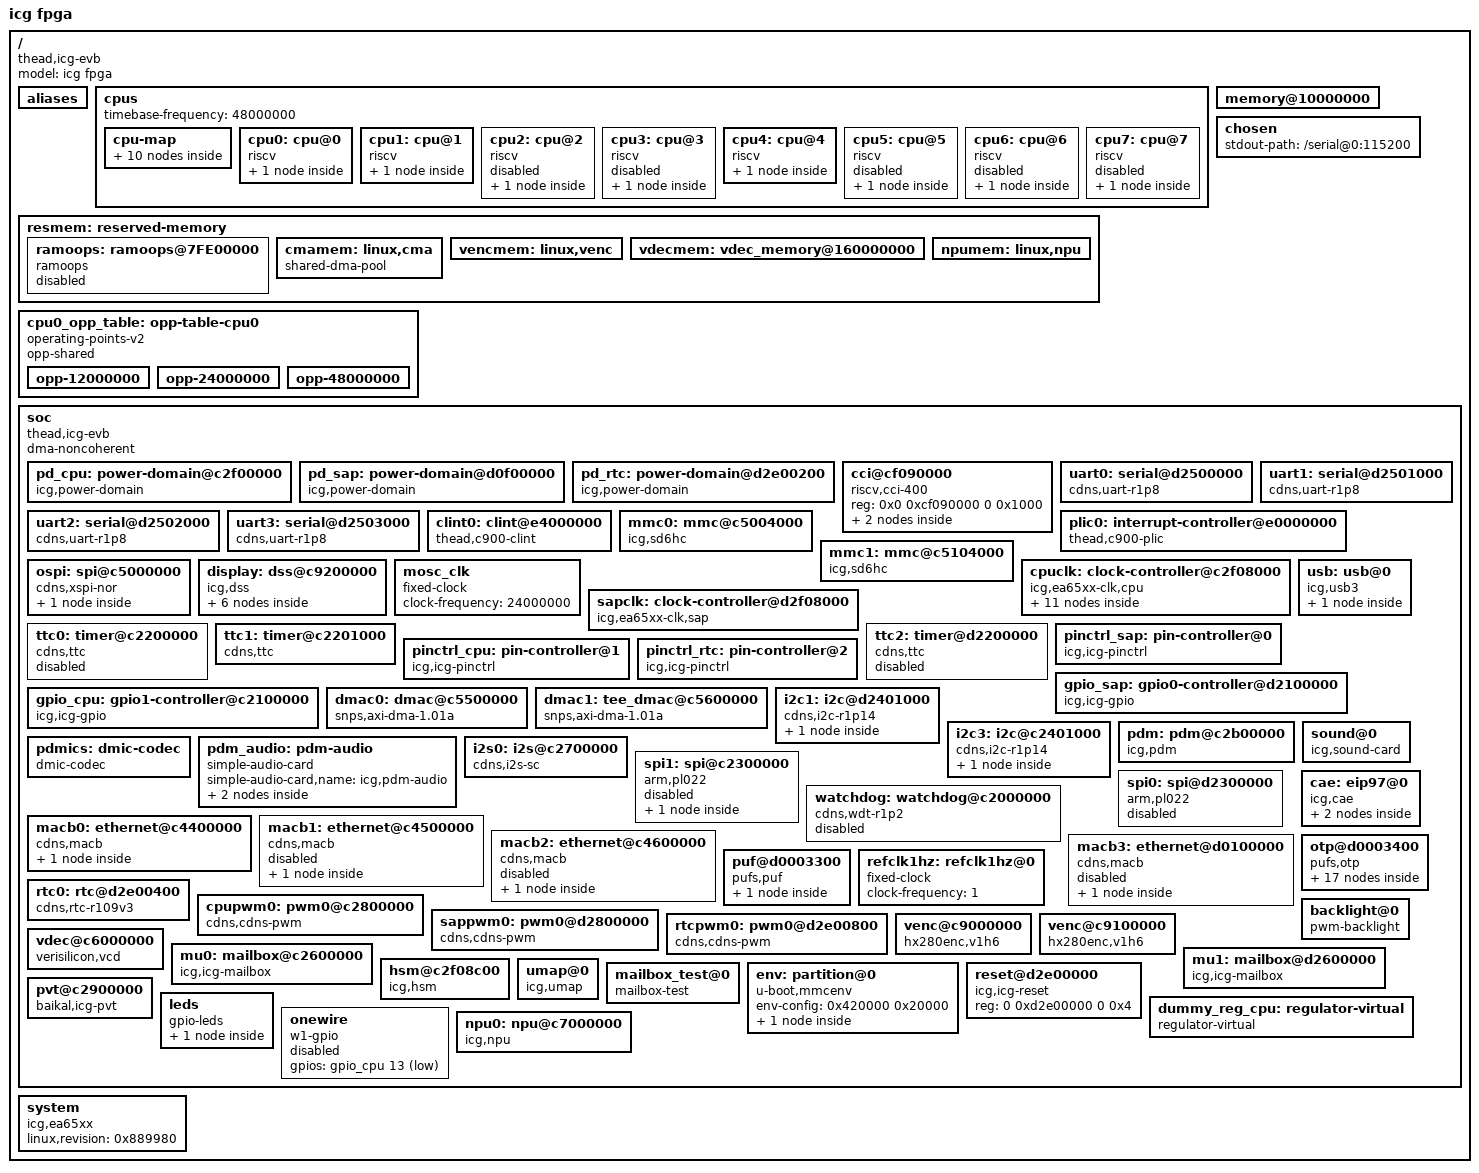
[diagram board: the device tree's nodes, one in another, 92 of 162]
/dts-v1/;
/ {
	model = "icg fpga";
	compatible = "thead,icg-evb";
	#address-cells = <2>;
	#size-cells = <2>;

	aliases {
		serial0 = &uart0;
		serial1 = &uart1;
		serial2 = &uart2;
		serial3 = &uart3;
		mmc0 = &mmc0;
		mmc1 = &mmc1;
		spi0 = &spi0;
		spi1 = &spi1;
		i2c1 = &i2c1;
		i2c3 = &i2c3;
		/*
			if no aliases provided, 
			driver will failed to get 
			index of a serial port, 
			lead to probe fail.
		*/
	};

	cpus {
		#address-cells = <1>;
		#size-cells = <0>;
		timebase-frequency = <48000000>;

		cpu-map {
			cluster0 {
				core0 {
					cpu = <&cpu0>;
				};
				core1 {
					cpu = <&cpu1>;
				};
				core2 {
					cpu = <&cpu2>;
				};
				core3 {
					cpu = <&cpu3>;
				};
			};
			cluster1 {
				core0 {
					cpu = <&cpu4>;
				};

				core1 {
					cpu = <&cpu5>;
				};

				core2 {
					cpu = <&cpu6>;
				};

				core3 {
					cpu = <&cpu7>;
				};
			};
		};

		cpu0:cpu@0 {
			device_type = "cpu";
			reg = <0>;
			status = "okay";
			compatible = "riscv";
			mmu-type = "riscv,sv39";
			riscv,isa = "rv64imafdc_zicbom_svpbmt_sstc_sscofpmf";
			riscv,cbom-block-size = <64>;
			cci-control-port = <&cci_control0>;
			cpu0_intc: interrupt-controller {
				#interrupt-cells = <1>;
				compatible = "riscv,cpu-intc";
				interrupt-controller;
			};
		};

		cpu1:cpu@1 {
			device_type = "cpu";
			reg = <1>;
			status = "okay";
			compatible = "riscv";
			mmu-type = "riscv,sv39";
			riscv,isa = "rv64imafdc_zicbom_svpbmt_sstc_sscofpmf";
			riscv,cbom-block-size = <64>;
			cci-control-port = <&cci_control0>;
			cpu1_intc: interrupt-controller {
				#interrupt-cells = <1>;
				compatible = "riscv,cpu-intc";
				interrupt-controller;
			};
		};

		cpu2:cpu@2 {
			device_type = "cpu";
			reg = <2>;
			status = "disabled";
			compatible = "riscv";
			mmu-type = "riscv,sv39";
			riscv,isa = "rv64imafdc_zicbom_svpbmt_sstc_sscofpmf";
			riscv,cbom-block-size = <64>;
			cci-control-port = <&cci_control0>;
			cpu2_intc: interrupt-controller {
				#interrupt-cells = <1>;
				compatible = "riscv,cpu-intc";
				interrupt-controller;
			};
		};

		cpu3:cpu@3 {
			device_type = "cpu";
			reg = <3>;
			status = "disabled";
			compatible = "riscv";
			mmu-type = "riscv,sv39";
			riscv,isa = "rv64imafdc_zicbom_svpbmt_sstc_sscofpmf";
			riscv,cbom-block-size = <64>;
			cci-control-port = <&cci_control0>;
			cpu3_intc: interrupt-controller {
				#interrupt-cells = <1>;
				compatible = "riscv,cpu-intc";
				interrupt-controller;
			};
		};

		cpu4:cpu@4 {
			device_type = "cpu";
			reg = <4>;
			status = "okay";
			compatible = "riscv";
			mmu-type = "riscv,sv39";
			riscv,isa = "rv64imafdc_zicbom_svpbmt_sstc_sscofpmf";
			riscv,cbom-block-size = <64>;
			cci-control-port = <&cci_control1>;
			cpu4_intc: interrupt-controller {
				#interrupt-cells = <1>;
				compatible = "riscv,cpu-intc";
				interrupt-controller;
			};
		};

		cpu5:cpu@5 {
			device_type = "cpu";
			reg = <5>;
			status = "disabled";
			compatible = "riscv";
			mmu-type = "riscv,sv39";
			riscv,isa = "rv64imafdc_zicbom_svpbmt_sstc_sscofpmf";
			riscv,cbom-block-size = <64>;
			cci-control-port = <&cci_control0>;
			cpu5_intc: interrupt-controller {
				#interrupt-cells = <1>;
				compatible = "riscv,cpu-intc";
				interrupt-controller;
			};
		};

		cpu6:cpu@6 {
			device_type = "cpu";
			reg = <6>;
			status = "disabled";
			compatible = "riscv";
			mmu-type = "riscv,sv39";
			riscv,isa = "rv64imafdc_zicbom_svpbmt_sstc_sscofpmf";
			riscv,cbom-block-size = <64>;
			cci-control-port = <&cci_control1>;
			cpu6_intc: interrupt-controller {
				#interrupt-cells = <1>;
				compatible = "riscv,cpu-intc";
				interrupt-controller;
			};
		};

		cpu7:cpu@7 {
			device_type = "cpu";
			reg = <7>;
			status = "disabled";
			compatible = "riscv";
			mmu-type = "riscv,sv39";
			riscv,isa = "rv64imafdc_zicbom_svpbmt_sstc_sscofpmf";
			riscv,cbom-block-size = <64>;
			cci-control-port = <&cci_control1>;
			cpu7_intc: interrupt-controller {
				#interrupt-cells = <1>;
				compatible = "riscv,cpu-intc";
				interrupt-controller;
			};
		};
	};

	memory@10000000{
		device_type = "memory";
		reg = <0x0 0x40200000 0x0 0x3fe00000
			0x1 0x40000000 0x0 0x40000000>;
	};

	chosen {
		stdout-path = "/serial@0:115200";
	};

	resmem: reserved-memory {
		#address-cells = <2>;
		#size-cells = <2>;
		ranges;

		ramoops: ramoops@7FE00000 {
			compatible = "ramoops";
			reg = <0x0 0x7FE00000 0x0 0x200000>;
			record-size = <0x8000>;
			console-size = <0x8000>;
			status = "disabled";
		};

		cmamem: linux,cma {
			compatible = "shared-dma-pool";
			reusable;
			size = <0 0x8000000>;
			alloc-ranges = <0 0x70000000 0 0xFE00000>;
			linux,cma-default;
		};

		vencmem: linux,venc {
			reg = <0x1 0x50000000 0x0 0x10000000>;
			no-map;
		};

		vdecmem: vdec_memory@160000000 {
			reg = <0x1 0x60000000 0x0 0x10000000>;
			no-map;
		};

		npumem: linux,npu {
		    reg = <0x1 0x80000000 0x0 0x10000000>;
			no-map;
		};
	};

	cpu0_opp_table: opp-table-cpu0 {
		compatible = "operating-points-v2";
		opp-shared;

		opp-12000000 {
			opp-hz = /bits/ 64 <12000000>;
			opp-microvolt = <600000>;
		};

		opp-24000000 {
			opp-hz = /bits/ 64 <24000000>;
			opp-microvolt = <700000>;
		};

		opp-48000000 {
			opp-hz = /bits/ 64 <48000000>;
			opp-microvolt = <800000>;
		};
	};

	soc {
		#address-cells = <2>;
		#size-cells = <2>;
		compatible = "thead,icg-evb", "simple-bus";
		dma-noncoherent;
		ranges;

		pd_cpu: power-domain@c2f00000 {
			compatible = "icg,power-domain";
			#power-domain-cells = <4>;
			domain-idx = <ICG_DOMAIN_CPU>;
			domain-nums = < 72 >;
		};

		pd_sap: power-domain@d0f00000 {
			compatible = "icg,power-domain";
			#power-domain-cells = <4>;
			domain-idx = <ICG_DOMAIN_SAP>;
			domain-nums = < 11 >;
		};

		pd_rtc: power-domain@d2e00200 {
			compatible = "icg,power-domain";
			#power-domain-cells = <4>;
			domain-idx = <ICG_DOMAIN_RTC>;
			domain-nums = < 2 >;
		};

		cci@cf090000 {
			compatible = "riscv,cci-400";
			#address-cells = <1>;
			#size-cells = <1>;
			reg = <0x0 0xcf090000 0 0x1000>;
			ranges = <0x0 0x0 0xcf090000 0x10000>;

			cci_control0: slave-if@5000 {
				compatible = "riscv,cci-400-ctrl-if";
				interface-type = "ace";
				reg = <0x5000 0x1000>;
			};

			cci_control1: slave-if@4000 {
				compatible = "riscv,cci-400-ctrl-if";
				interface-type = "ace";
				reg = <0x4000 0x1000>;
			};
		};

		uart0:serial@d2500000 {
				compatible = "cdns,uart-r1p8";
				reg = <0x0 0xd2500000 0x0 0x1000>;
				interrupt-parent = <&plic0>;
				interrupts = <S_UART0_IRQn IRQ_TYPE_LEVEL_HIGH>;
				clocks = <&sapclk  EA65XX_S_APB_CLK>, <&sapclk  EA65XX_S_UART_CLK>;
                clock-names = "pclk", "uart_clk";
				//power-domains = <&pd_sap EA65XX_PD_UART0_SAP ALWAYS_ON>;
		};

		uart1:serial@d2501000 {
        		compatible = "cdns,uart-r1p8";
        		reg = <0x0 0xd2501000 0x0 0x0400>;
        		interrupt-parent = <&plic0>;
        		interrupts = <S_UART1_IRQn IRQ_TYPE_LEVEL_HIGH>;
        		pinctrl-names = "default";
        		pinctrl-0 = <&pin_uart1>;
        		power-domains = <&pd_sap EA65XX_PD_UART1_SAP NORMAL>;
        		clocks = <&sapclk EA65XX_S_APB_CLK>, <&sapclk EA65XX_S_UART_CLK>;
        		clock-names = "pclk", "uart_clk";
		};

		uart2:serial@d2502000 {
        		compatible = "cdns,uart-r1p8";
        		reg = <0x0 0xd2502000 0x0 0x0400>;
        		interrupt-parent = <&plic0>;
        		interrupts = <C_UART2_IRQn IRQ_TYPE_LEVEL_HIGH>;
        		pinctrl-names = "default";
        		pinctrl-0 = <&pin_uart2>;
        		power-domains = <&pd_cpu EA65XX_PD_UART2_CPU NORMAL>;
        		clocks = <&cpuclk EA65XX_PAPB_CLK>, <&cpuclk EA65XX_UART_CLK>;
        		clock-names = "pclk", "uart_clk";
		};

		uart3:serial@d2503000 {
        		compatible = "cdns,uart-r1p8";
        		reg = <0x0 0xd2503000 0x0 0x0400>;
        		interrupt-parent = <&plic0>;
        		interrupts = <C_UART3_IRQn IRQ_TYPE_LEVEL_HIGH>;
        		pinctrl-names = "default";
        		pinctrl-0 = <&pin_uart3>;
        		power-domains = <&pd_cpu EA65XX_PD_UART3_CPU NORMAL>;
        		clocks = <&cpuclk EA65XX_PAPB_CLK>, <&cpuclk EA65XX_UART_CLK>;
        		clock-names = "pclk", "uart_clk";
		};

		clint0: clint@e4000000 {
			compatible = "thead,c900-clint";
			interrupts-extended = <
				&cpu0_intc 3 &cpu0_intc 7
				&cpu1_intc 3 &cpu1_intc 7
				&cpu2_intc 3 &cpu2_intc 7
				&cpu3_intc 3 &cpu3_intc 7
				&cpu4_intc 3 &cpu4_intc 7
				&cpu5_intc 3 &cpu5_intc 7
				&cpu6_intc 3 &cpu6_intc 7
				&cpu7_intc 3 &cpu7_intc 7
				>;
			reg = <0x0 0xe4000000 0x0 0x10000>;
			clint,has-no-64bit-mmio;
		};
	
		plic0: interrupt-controller@e0000000 {
			compatible = "thead,c900-plic";
			interrupt-controller;
			interrupts-extended = <
				&cpu0_intc  0xffffffff &cpu0_intc 9
				&cpu1_intc  0xffffffff &cpu1_intc 9
				&cpu2_intc  0xffffffff &cpu2_intc 9
				&cpu3_intc  0xffffffff &cpu3_intc 9
				&cpu4_intc  0xffffffff &cpu4_intc 9
				&cpu5_intc  0xffffffff &cpu6_intc 9
				&cpu6_intc  0xffffffff &cpu6_intc 9
				&cpu7_intc  0xffffffff &cpu7_intc 9
				>;
			reg = <0x0 0xe0000000 0x0 0x04000000>;
			#address-cells = <0>;
			#interrupt-cells = <2>;
			riscv,ndev = <194>;
		};

		mmc0: mmc@c5004000 {
			compatible = "icg,sd6hc";
			clock-names = "main";
			clocks = <&cpuclk EA65XX_EMMC0_CLK>;
			clock-frequency = <36000000>;
			reg = <0x0 0xc5004000 0x0 0x400>;
			power-domains = <&pd_cpu EA65XX_PD_EMMC0_CPU ALWAYS_ON>;
			interrupts-extended = <&plic0 C_EMMC0_IRQn IRQ_TYPE_LEVEL_HIGH>;
			bus-width = <1>;
			sdhci-caps-mask = <0x0 0x200000>;
			status = "disabled";
		};

		mmc1: mmc@c5104000 {
			compatible = "icg,sd6hc";
			clock-names = "main";
			clocks = <&cpuclk EA65XX_SD1_CLK>;
			clock-frequency = <36000000>;
			reg = <0x0 0xc5104000 0x0 0x400>;
			power-domains = <&pd_cpu EA65XX_PD_SD1_CPU ALWAYS_ON>;
			interrupts-extended = <&plic0 C_SD1_IRQn IRQ_TYPE_LEVEL_HIGH>;
			bus-width = <1>;
			sdhci-caps-mask = <0x0 0x200000>;
			no-1-8-v;
			status = "disabled";
		};

		ospi: spi@c5000000 {
			compatible = "cdns,xspi-nor";
			reg = <0x0 0xc5000000 0x0 0x1000>,
				<0x0 0x30000000 0x0 0x1000>,
				<0x0 0xC5f00000 0x0 0x1000>;
			reg-names = "io", "sdma", "pwr";
			interrupts-extended = <&plic0 C_XSPI0_IRQn IRQ_TYPE_LEVEL_HIGH>;
			pinctrl-names = "default";
			pinctrl-0 = <&pin_ospi>;
			status = "okay";
			#address-cells = <1>;
			#size-cells = <0>;

			flash@0 {
				compatible = "w25q128", "jedec,spi-nor";
				reg = <0>;/* Chip select must be 0/1 */
				#address-cells = <1>;
				#size-cells = <1>;
				spi-max-frequency = <4000000>;
			};
		};
		
		display: dss@c9200000 {
			compatible = "icg,dss";
			clocks = <&cpuclk  EA65XX_IDS_ETC_CLK>, <&cpuclk  EA65XX_IDS_EITF_CLK>;
			clock-names = "ids_etc", "ids_eitf";
			power-domains = <&pd_cpu EA65XX_PD_IDS_CPU ALWAYS_ON>;
			pinctrl-names = "default";
			pinctrl-0 = <&pin_ids>;
			status = "okay";
			port = "lcdc"; //lcdc or tvif
			det-gpios = <&gpio_cpu 89 GPIO_ACTIVE_HIGH>;
			overlay-nums = <1>;
			#address-cells = <2>;
			#size-cells = <2>;
			ranges;

			dispc@c9200000 {
				compatible = "icg,dispc";
				reg = <0x00 0xc9200000 0x00 0x8000>;
				interrupts-extended = <&plic0 C_IDS_IRQn IRQ_TYPE_LEVEL_HIGH>;
				interrupts = <25>;
			};

			lcdc@c9200000 {
				compatible = "icg,lcdc";
				bpp = <32>;
				reset-gpios = <&gpio_cpu 78 GPIO_ACTIVE_HIGH>;
				backlight-gpios = <&gpio_cpu 79 GPIO_ACTIVE_HIGH>;
				display-timings {
					native-mode = <&timing0>;
					timing0: 1024x600 {
						clock-frequency = <50000000>;
						hactive = <1024>;
						vactive = <600>;
						hfront-porch = <160>;
						hback-porch = <140>;
						hsync-len = <20>;
						vfront-porch = <12>;
						vback-porch = <20>;
						vsync-len = <3>;
						hsync-active = <0>;
						vsync-active = <0>;
						de-active = <0>;
						pixelclk-active = <0>;
					};
				};
			};

			tvif@c9200000 {
				compatible = "icg,tvif";
				mode = "bt1120"; //bt601 bt656
				standard = "pal";//"ntsc"
				width = <1280>;
				height = <720>;
			};

			fb@c9200000 {
				compatible = "icg,fb";
				status = "okay";
			};
		};

        mosc_clk: mosc_clk {
            #clock-cells = <0>;
            compatible = "fixed-clock";
            clock-frequency = <24000000>;
        };

		cpuclk: clock-controller@c2f08000 {
			#address-cells = <2>;
			#size-cells = <2>;
			clk-domain = <ICG_DOMAIN_CPU>;
			compatible = "icg,ea65xx-clk,cpu";
			reg = <0x0 0xc2f08000 0x0 0x1000>;
			#clock-cells = <1>;
			c_apll_clk {
				assigned-clocks = <&cpuclk EA65XX_APLL_CLK>;
				assigned-clock-rates = <48000000>;
			};

			c_dpll_clk {
				assigned-clocks = <&cpuclk EA65XX_DPLL_CLK>;
				assigned-clock-rates = <96000000>;
			};

			c_epll_clk {
				assigned-clocks = <&cpuclk EA65XX_EPLL_CLK>;
				assigned-clock-rates = <96000000>;
			};

			c_vpll_clk {
				assigned-clocks = <&cpuclk EA65XX_VPLL_CLK>;
				assigned-clock-rates = <96000000>;
			};

			c_bpll_clk {
				assigned-clocks = <&cpuclk EA65XX_BPLL_CLK>;
				assigned-clock-rates = <96000000>;
			};

			c_bus1_clk {
				assigned-clocks = <&cpuclk EA65XX_BUS1_CLK>;
				assigned-clock-rates = <96000000>;
			};

			c_bus2_clk {
				assigned-clocks = <&cpuclk EA65XX_BUS2_CLK>;
				assigned-clock-rates = <48000000>;
			};

			c_bus3_clk {
				assigned-clocks = <&cpuclk EA65XX_BUS3_CLK>;
				assigned-clock-rates = <48000000>;
			};

			c_bus4_clk {
				assigned-clocks = <&cpuclk EA65XX_BUS4_CLK>;
				assigned-clock-rates = <96000000>;
			};

			c_bus5_clk {
				assigned-clocks = <&cpuclk EA65XX_BUS5_CLK>;
				assigned-clock-rates = <24000000>;
			};

			c_bus6_clk {
				assigned-clocks = <&cpuclk EA65XX_BUS6_CLK>;
				assigned-clock-rates = <12000000>;
			};
		};

		sapclk: clock-controller@d2f08000 {
			#address-cells = <2>;
			#size-cells = <2>;
			clk-domain = <ICG_DOMAIN_SAP>;
			compatible = "icg,ea65xx-clk,sap";
			reg = <0x0 0xd2f08000 0x0 0x1000>;
			#clock-cells = <1>;
		};

		ttc0: timer@c2200000 {
			interrupts-extended =
				<&plic0 C_TTC0_TIMER0_IRQn IRQ_TYPE_LEVEL_HIGH>,
				<&plic0 C_TTC0_TIMER1_IRQn IRQ_TYPE_LEVEL_HIGH>,
				<&plic0 C_TTC0_TIMER2_IRQn IRQ_TYPE_LEVEL_HIGH>;
			power-domains = <&pd_cpu EA65XX_PD_TTC0_CPU ALWAYS_ON>;
			compatible = "cdns,ttc";
			clocks = <&cpuclk EA65XX_TTC_CLK>;
			timer-width = <32>;
			reg = <0x0 0xc2200000 0x0 0x1000>;
			status = "disable";
		};

		ttc1: timer@c2201000 {
			interrupts-extended =
				<&plic0 C_TTC1_TIMER0_IRQn IRQ_TYPE_LEVEL_HIGH>,
				<&plic0 C_TTC1_TIMER1_IRQn IRQ_TYPE_LEVEL_HIGH>,
				<&plic0 C_TTC1_TIMER2_IRQn IRQ_TYPE_LEVEL_HIGH>;
			power-domains = <&pd_cpu EA65XX_PD_TTC1_CPU ALWAYS_ON>;
			compatible = "cdns,ttc";
			clocks = <&cpuclk EA65XX_TTC_CLK>;
			timer-width = <32>;
			reg = <0x0 0xc2201000 0x0 0x1000>;
			status = "okay";
		};

		ttc2: timer@d2200000 {
			interrupts-extended =
				<&plic0 S_TTC0_TIMER0_IRQn IRQ_TYPE_LEVEL_HIGH>,
				<&plic0 S_TTC0_TIMER1_IRQn IRQ_TYPE_LEVEL_HIGH>,
				<&plic0 S_TTC0_TIMER2_IRQn IRQ_TYPE_LEVEL_HIGH>;
			power-domains = <&pd_sap EA65XX_PD_TTC_SAP ALWAYS_ON>;
			compatible = "cdns,ttc";
			clocks = <&sapclk  EA65XX_S_TTC_CLK>;
			timer-width = <32>;
			reg = <0x0 0xd2200000 0x0 0x1000>;
			status = "disable";
		};

		pinctrl_sap: pin-controller@0{
			reg = <0 0xd2f09000 0 0x400>;
			compatible = "icg,icg-pinctrl";
			pin-domain = <ICG_DOMAIN_SAP>;
			pin-base = <ICG_PIN_SAP_START>;
			npins = <ICG_PIN_PER_DOMAIN_CNT>;
		};

		pinctrl_cpu: pin-controller@1{
			reg = <0 0xc2f09000 0 0x400>;
			compatible = "icg,icg-pinctrl";
			pin-domain = <ICG_DOMAIN_CPU>;
			pin-base = <ICG_PIN_CPU_START>;
			npins = <ICG_PIN_PER_DOMAIN_CNT>;
		};

		pinctrl_rtc: pin-controller@2{
			reg = <0 0xd2e00040 0 0x40>;
			compatible = "icg,icg-pinctrl";
			pin-domain = <ICG_DOMAIN_RTC>;
			pin-base = <ICG_PIN_RTC_START>;
			npins = <ICG_PIN_PER_DOMAIN_CNT>;
		};

		usb: usb@0  {
			compatible = "icg,usb3";
			power-domains = <&pd_cpu EA65XX_PD_USB0_CPU NORMAL>;
			clocks = <&cpuclk EA65XX_USB_LPM_CLK>, 
					<&cpuclk EA65XX_USB_APP_CLK>,
					<&cpuclk EA65XX_USB_STB_CLK>,
					<&cpuclk EA65XX_USB2_REF_CLK>,
					<&cpuclk EA65XX_USB3_REF_CLK>;
			clock-names = "lpm", "app", "stb", "ref2", "ref3";
			//assigned-clocks = <&cpuclk IMX_SC_R_USB_2 IMX_SC_PM_CLK_MST_BUS>;
			//assigned-clock-rates = <250000000>;
			usb0_id_det-gpios = <&gpio_cpu 89 GPIO_ACTIVE_HIGH>;
			//usb1_id_det-gpios = <&gpio_cpu 90 GPIO_ACTIVE_HIGH>;
			//usb2_id_det-gpios = <&gpio_cpu 91 GPIO_ACTIVE_HIGH>;
			//usb3_id_det-gpios = <&gpio_cpu 92 GPIO_ACTIVE_HIGH>;

			#address-cells = <2>;
			#size-cells = <2>;
			ranges;

			usb0: usb@c4000000 {
				compatible = "cdns,usb3";
				reg = <0x00 0xc4000000 0x00 0x10000>,
					  <0x00 0xc4010000 0x00 0x10000>,
					  <0x00 0xc4020000 0x00 0x10000>;
				reg-names = "otg", "xhci", "dev";
				interrupt-parent = <&plic0>;
				interrupts = <C_USB0_HOST_IRQn	IRQ_TYPE_LEVEL_HIGH
							C_USB0_DEVICE_IRQn	IRQ_TYPE_LEVEL_HIGH
							C_USB0_OTG_IRQn		IRQ_TYPE_LEVEL_HIGH>;
				interrupt-names = "host", "peripheral", "otg";
				maximum-speed = "super-speed";
				dr_mode = "peripheral";
			};
		};

		gpio_sap: gpio0-controller@d2100000 {
			compatible = "icg,icg-gpio";
			reg = <0x0 0xd2100000 0x0 0x1000>;
			power-domains = <&pd_sap EA65XX_PD_GPIO_SAP ALWAYS_ON>;
			#gpio-cells = <2>;
			gpio-base = <ICG_PIN_SAP_START>;
			ngpios = <18>;
			gpio-controller;
			interrupt-controller;
			interrupt-parent = <&plic0>;
			interrupts = <S_GPIO0_IRQn IRQ_TYPE_LEVEL_HIGH>;
		};

		gpio_cpu: gpio1-controller@c2100000 {
			compatible = "icg,icg-gpio";
			reg = <0x0 0xc2100000 0x0 0x1000>;
			power-domains = <&pd_cpu EA65XX_PD_GPIO_CPU ALWAYS_ON>;
			#gpio-cells = <2>;
			gpio-base = <ICG_PIN_CPU_START>;
			ngpios = <99>;
			gpio-controller;
			interrupt-controller;
			interrupt-parent = <&plic0>;
			interrupts = 	<C_GPIO0_IRQn IRQ_TYPE_LEVEL_HIGH>,
							<C_GPIO1_IRQn IRQ_TYPE_LEVEL_HIGH>,
							<C_GPIO2_IRQn IRQ_TYPE_LEVEL_HIGH>,
							<C_GPIO3_IRQn IRQ_TYPE_LEVEL_HIGH>;
		};

		dmac0: dmac@c5500000 {
			compatible = "snps,axi-dma-1.01a";
			reg = <0x0 0xc5500000 0x0 0x1000>;
			interrupt-parent = <&plic0>;
			interrupts = <C_DMA0_IRQn IRQ_TYPE_LEVEL_HIGH>;
			dma-noncoherent;
			clocks = <&cpuclk EA65XX_BUS2_CLK>, <&cpuclk EA65XX_PAPB_CLK>;
			clock-names = "core-clk", "cfgr-clk";
			power-domains = <&pd_cpu EA65XX_PD_DMA0_CPU ALWAYS_ON>;
			#dma-cells = <1>;
			dma-channels = <8>;
			snps,block-size = <65536 65536 65536 65536 65536 65536 65536 65536>;
			snps,priority = <0 1 2 3 4 5 6 7>;
			snps,dma-masters = <1>;
			snps,data-width = <4>;
			snps,axi-max-burst-len = <16>;
			status = "okay";
		};

		dmac1: tee_dmac@c5600000 {
			compatible = "snps,axi-dma-1.01a";
			reg = <0x0 0xc5600000 0x0 0x1000>;
			interrupt-parent = <&plic0>;
			interrupts = <C_DMA1_IRQn IRQ_TYPE_LEVEL_HIGH>;
			dma-noncoherent;
			clocks = <&cpuclk EA65XX_BUS2_CLK>, <&cpuclk EA65XX_PAPB_CLK>;
			clock-names = "core-clk", "cfgr-clk";
			power-domains = <&pd_cpu EA65XX_PD_DMA1_CPU ALWAYS_ON>;
			#dma-cells = <1>;
			dma-channels = <8>;
			snps,block-size = <65536 65536 65536 65536 65536 65536 65536 65536>;
			snps,priority = <0 1 2 3 4 5 6 7>;
			snps,dma-masters = <1>;
			snps,data-width = <4>;
			snps,axi-max-burst-len = <16>;
			status = "okay";
		};

		i2c1: i2c@d2401000 {
			compatible = "cdns,i2c-r1p14";
			reg = <0x0 0xd2401000 0x0 0x1000>;
			#address-cells = <1>;
			#size-cells = <0>;
			interrupt-parent = <&plic0>;
			interrupts = <S_IIC1_IRQn IRQ_TYPE_LEVEL_HIGH>;
			clock-frequency = <100000>;
			clocks = <&sapclk  EA65XX_S_APB_CLK>;
			power-domains = <&pd_sap EA65XX_PD_IIC1_SAP ALWAYS_ON>;
			pinctrl-names = "default";
			pinctrl-0 = <&pin_i2c1>;

			eeprom@50{
				compatible = "slave-24c02";
				reg = <0x50>;
				pagesize = <1>;
			};
		};
		
		i2c3: i2c@c2401000 {
			compatible = "cdns,i2c-r1p14";
			reg = <0x0 0xc2401000 0x0 0x1000>;
			#address-cells = <1>;
			#size-cells = <0>;
			interrupt-parent = <&plic0>;
			interrupts = <C_IIC3_IRQn IRQ_TYPE_LEVEL_HIGH>;
			clock-frequency = <100000>;
			clocks = <&cpuclk EA65XX_PAPB_CLK>;
			power-domains = <&pd_cpu EA65XX_PD_IIC3_CPU ALWAYS_ON>;
			pinctrl-names = "default";
			pinctrl-0 = <&pin_i2c3>;

			es8388: codec@11{
				compatible = "everest,es8388";
				reg = <0x11>;
				pagesize = <1>;
			};
		};

		pdm: pdm@c2b00000 {
			compatible = "icg,pdm";
			reg = <0x0 0xc2b00000 0x0 0x4000>;
			//interrupt-parent = <&plic0>;
			//interrupts = <C_DMAC0_IRQn IRQ_TYPE_LEVEL_HIGH>;
			dmas = <&dmac1 6>, <&dmac1 7>, <&dmac1 8>, <&dmac1 9>;
			dma-names = "rx0", "rx1", "rx2", "rx3";
			multi-dma-rx = <1>;
			mul-dma-rx-num = <4>;
			clocks = <&cpuclk EA65XX_DMIC_CLK>;
			clock-names = "pdm-clk";
			pinctrl-names = "default";
			pinctrl-0 = <&pin_dmic>;
			power-domains = <&pd_cpu EA65XX_PD_DMIC_CPU ALWAYS_ON>;
			#sound-dai-cells = <0>;
			status = "okay";
		};

		pdmics: dmic-codec {
			status = "okay";
			compatible = "dmic-codec";
			#sound-dai-cells = <0>;
		};

		pdm_audio: pdm-audio {
			status = "okay";
			compatible = "simple-audio-card";
			simple-audio-card,name = "icg,pdm-audio";
			simple-audio-card,cpu {
				sound-dai = <&pdm>;
			};
			simple-audio-card,codec {
				sound-dai = <&pdmics>;
			};
		};

		i2s0: i2s@c2700000 {
			compatible = "cdns,i2s-sc";
			reg = <0x0 0xc2700000 0x0 0x1000>;
			#address-cells = <1>;
			#size-cells = <0>;
			//interrupt-parent = <&plic0>;
			//interrupts = <C_IIS0_IRQn IRQ_TYPE_LEVEL_HIGH>;
			clocks = <&cpuclk EA65XX_IIS_CLK>;
			power-domains = <&pd_cpu EA65XX_PD_IIS0_CPU ALWAYS_ON>;
			pinctrl-names = "default";
			pinctrl-0 = <&pin_i2s0>;
			dmas = <&dmac0 10>, <&dmac0 11>;
			dma-names = "tx","rx";
		};

		sound@0 {
			compatible = "icg,sound-card";
			i2s-controller = <&i2s0>;
			sound-codec = <&es8388>;
		};

		spi1: spi@c2300000 {
			compatible = "arm,pl022", "arm,primecell";
			arm,primecell-periphid = <0x00041022>;
			reg = <0x0 0xc2300000 0x0 0x1000>;
			interrupts-extended = <&plic0 C_SPI1_IRQn IRQ_TYPE_LEVEL_HIGH>;
			#address-cells = <1>;
			#size-cells = <0>;
			num-cs = <1>;
			power-domains = <&pd_cpu EA65XX_PD_SPI1_CPU NORMAL>;
			pinctrl-names = "default";
			pinctrl-0 = <&pin_spi1>;
			cs-gpios = <&gpio_cpu 48 GPIO_ACTIVE_LOW>;
			status = "disabled";
			clocks = <&sapclk  EA65XX_S_SSP_CLK>;
			clock-names = "apb_pclk";
			flash0:flash@0 {
				compatible = "w25q128", "jedec,spi-nor";
				reg = <0>;   
				spi-max-frequency = <4000000>;
				
			};
		};

		spi0: spi@d2300000 {
			compatible = "arm,pl022", "arm,primecell";
			arm,primecell-periphid = <0x00041022>;
			reg = <0x0 0xd2300000 0x0 0x1000>;
			interrupts-extended = <&plic0 S_SPI0_IRQn IRQ_TYPE_LEVEL_HIGH>;
			#address-cells = <1>;
			#size-cells = <0>;
			num-cs = <1>;
			power-domains = <&pd_sap EA65XX_PD_SPI0_SAP NORMAL>;
			pinctrl-names = "default";
			pinctrl-0 = <&pin_spi0>;
			cs-gpios = <&gpio_sap 7 GPIO_ACTIVE_LOW>;
			status = "disabled";
			clocks = <&sapclk  EA65XX_S_SSP_CLK>;
			clock-names = "apb_pclk";
		};

		watchdog: watchdog@c2000000 {
			compatible = "cdns,wdt-r1p2";
			reg = <0x0 0xc2000000 0x0 0x1000>;
			interrupts-extended = <&plic0 C_WDT_IRQn IRQ_TYPE_LEVEL_HIGH>;
			power-domains = <&pd_cpu EA65XX_PD_WDT_CPU ALWAYS_ON>;
			clocks = <&cpuclk EA65XX_PAPB_CLK>;
			reset-on-timeout = <1>;
			status = "disabled";
		};

		macb0: ethernet@c4400000 {
			compatible = "cdns,macb";
			reg = <0x0 0xc4400000 0x0 0x2000
				0x0 0xc4f01000 0x0 0x2000>;
			power-domains = <&pd_cpu EA65XX_PD_GMAC0_CPU NORMAL>;
			clock-names = "pclk", "hclk", "tx_clk", "rx_clk", "tsu_clk";
			clocks = <&cpuclk EA65XX_PAPB_CLK>, <&cpuclk EA65XX_GMAC_GTX_CLK>, <&cpuclk EA65XX_GMAC_REF_CLK>, <&cpuclk EA65XX_GMAC_REF_CLK>, <&cpuclk EA65XX_GMAC_TSU_CLK>;
			interrupts = <C_GMAC0_Q_IRQn IRQ_TYPE_LEVEL_HIGH>,
								   <C_GMAC0_Q_IRQn IRQ_TYPE_LEVEL_HIGH>,
									 <C_GMAC0_Q_IRQn IRQ_TYPE_LEVEL_HIGH>;
			interrupt-parent = <&plic0>;
			pinctrl-names = "default";
			pinctrl-0 = <&pin_macb0>;
			phy-mode = "rmii";
			local-mac-address = [e6 e8 dc ff db de];
			reset-gpios = <&gpio_cpu 41 GPIO_ACTIVE_LOW>;
			reset-delay-us = <150000>;
			reset-post-delay-us = <100000>;
			status = "okay";
			#address-cells = <1>;
			#size-cells = <0>;

			ethernet-phy@0 {
				compatible = "ethernet-phy-ieee802.3-c22";
				reg = <0x0>;
			};
		};

		macb1: ethernet@c4500000 {
			compatible = "cdns,macb";
			reg = <0x0 0xc4500000 0x0 0x2000
				0x0 0xc4f01400 0x0 0x2000>;
			power-domains = <&pd_cpu EA65XX_PD_GMAC1_CPU NORMAL>;
			clock-names = "pclk", "hclk", "tx_clk", "rx_clk", "tsu_clk";
			clocks = <&cpuclk EA65XX_PAPB_CLK>, <&cpuclk EA65XX_GMAC_GTX_CLK>, <&cpuclk EA65XX_GMAC_REF_CLK>, <&cpuclk EA65XX_GMAC_REF_CLK>, <&cpuclk EA65XX_GMAC_TSU_CLK>;
			interrupts = <C_GMAC1_Q_IRQn IRQ_TYPE_LEVEL_HIGH>,
								 	 <C_GMAC1_Q_IRQn IRQ_TYPE_LEVEL_HIGH>,
									 <C_GMAC1_Q_IRQn IRQ_TYPE_LEVEL_HIGH>;
			interrupt-parent = <&plic0>;
			pinctrl-names = "default";
			pinctrl-0 = <&pin_macb1>;
			phy-mode = "rgmii";
			local-mac-address = [e6 e8 dc ff db de];
			reset-gpios = <&gpio_cpu 57 GPIO_ACTIVE_LOW>;
			reset-delay-us = <150000>;
			reset-post-delay-us = <100000>;
			txc-skew-ps = <0>;
			rxc-skew-ps = <0>;
			status = "disabled";
			#address-cells = <1>;
			#size-cells = <0>;

			ethernet-phy@0 {
				compatible = "ethernet-phy-ieee802.3-c22";
				reg = <0x0>;
			};
		};

		macb2: ethernet@c4600000 {
			compatible = "cdns,macb";
			reg = <0x0 0xc4600000 0x0 0x100000
				0x0 0xc4f01800 0x0 0x400>;
			power-domains = <&pd_cpu EA65XX_PD_GMAC2_CPU NORMAL>;
			clock-names = "pclk", "hclk", "tx_clk", "rx_clk", "tsu_clk";
			clocks = <&cpuclk EA65XX_PAPB_CLK>, <&cpuclk EA65XX_GMAC_GTX_CLK>, <&cpuclk EA65XX_GMAC_REF_CLK>, <&cpuclk EA65XX_GMAC_REF_CLK>, <&cpuclk EA65XX_GMAC_TSU_CLK>;
			interrupts = <C_GMAC2_Q_IRQn IRQ_TYPE_LEVEL_HIGH>,
									 <C_GMAC2_Q_IRQn IRQ_TYPE_LEVEL_HIGH>,
									 <C_GMAC2_Q_IRQn IRQ_TYPE_LEVEL_HIGH>;
			interrupt-parent = <&plic0>;
			pinctrl-names = "default";
			pinctrl-0 = <&pin_macb2>;
			phy-mode = "rgmii";
			local-mac-address = [e6 e8 dc ff db de];
			reset-gpios = <&gpio_cpu 57 GPIO_ACTIVE_LOW>;
			reset-delay-us = <150000>;
			reset-post-delay-us = <100000>;
			txc-skew-ps = <0>;
			rxc-skew-ps = <0>;
			status = "disabled";
			#address-cells = <1>;
			#size-cells = <0>;

			ethernet-phy@0 {
				compatible = "ethernet-phy-ieee802.3-c22";
				reg = <0x0>;
			};
		};

		macb3: ethernet@d0100000 {
			compatible = "cdns,macb";
			reg = <0x0 0xd0100000 0x0 0x100000
				0x0 0xd0f00400 0x0 0x400>;
			power-domains = <&pd_sap EA65XX_PD_GMAC3_SAP NORMAL>;
			clock-names = "pclk", "hclk", "tx_clk", "rx_clk", "tsu_clk";
			clocks = <&cpuclk EA65XX_PAPB_CLK>, <&cpuclk EA65XX_GMAC_GTX_CLK>, <&cpuclk EA65XX_GMAC_REF_CLK>, <&cpuclk EA65XX_GMAC_REF_CLK>, <&cpuclk EA65XX_GMAC_TSU_CLK>;
			interrupts = <S_GMAC3_Q_IRQn IRQ_TYPE_LEVEL_HIGH>,
									 <S_GMAC3_Q_IRQn IRQ_TYPE_LEVEL_HIGH>,
									 <S_GMAC3_Q_IRQn IRQ_TYPE_LEVEL_HIGH>;
			interrupt-parent = <&plic0>;
			pinctrl-names = "default";
			pinctrl-0 = <&pin_macb3>;
			phy-mode = "rgmii";
			local-mac-address = [e6 e8 dc ff db de];
			reset-gpios = <&gpio_cpu 57 GPIO_ACTIVE_LOW>;
			reset-delay-us = <150000>;
			reset-post-delay-us = <100000>;
			txc-skew-ps = <0>;
			rxc-skew-ps = <0>;
			status = "disabled";
			#address-cells = <1>;
			#size-cells = <0>;

			ethernet-phy@0 {
				compatible = "ethernet-phy-ieee802.3-c22";
				reg = <0x0>;
			};
		};

		cae: eip97@0 {
			compatible = "icg,cae";
			power-domains = <&pd_cpu EA65XX_PD_CAE_CPU NORMAL>;
			clocks = <&cpuclk EA65XX_CAE_PERI_CLK>;
			clock-names = "peri";
			#address-cells = <2>;
			#size-cells = <2>;
			ranges;
			cae_0: eip97_0@c5400000 {
				compatible = "security-ip-97";
				power-domains = <&pd_cpu EA65XX_PD_CAE0_CPU NORMAL>;
				interrupt-parent = <&plic0>;
				interrupts = <C_CAE4_IRQn IRQ_TYPE_LEVEL_HIGH>,
					     <C_CAE0_IRQn IRQ_TYPE_LEVEL_HIGH>,
					     <C_CAE1_IRQn IRQ_TYPE_LEVEL_HIGH>,
					     <C_CAE2_IRQn IRQ_TYPE_LEVEL_HIGH>,
					     <C_CAE3_IRQn IRQ_TYPE_LEVEL_HIGH>;
				reg = <0x0 0xc5400000 0x0 0x80000>;
			};
			cae_1: eip97_1@c5480000 {
				compatible = "security-ip-97";
				power-domains = <&pd_cpu EA65XX_PD_CAE1_CPU NORMAL>;
				interrupt-parent = <&plic0>;
				interrupts = <C_CAE9_IRQn IRQ_TYPE_LEVEL_HIGH>,
					     <C_CAE5_IRQn IRQ_TYPE_LEVEL_HIGH>,
					     <C_CAE6_IRQn IRQ_TYPE_LEVEL_HIGH>,
					     <C_CAE7_IRQn IRQ_TYPE_LEVEL_HIGH>,
					     <C_CAE8_IRQn IRQ_TYPE_LEVEL_HIGH>;
				reg = <0x0 0xc5480000 0x0 0x80000>;
			};
		};

		otp@d0003400 {
			compatible = "pufs,otp";
			reg = <0x0 0xd0003400 0x0 0x400>, <0x0 0xd2f09404 0x0 0x4>;
			power-domains = <&pd_cpu EA65XX_PD_PUFCC_SAP ALWAYS_ON>;
			#address-cells = <1>;
			#size-cells = <1>;
			check-secure-flag;

			secure_boot: otp@0 {
				reg = <0 4>;
			};
			cpu: otp@4 {
				reg = <4 1>;
			};
			npu: otp@5 {
				reg = <5 1>;
			};
			fatfs: otp@6 {
				reg = <6 1>;
			};
			dlyline_1000m: otp@7 {
				reg = <7 9>;
			};
			dlyline_100m: otp@16 {
				reg = <16 9>;
			};
			user_data0: otp@25 {
				reg = <25 7>;
			};
			pub_hash: otp@32 {
				reg = <32 96>;
			};
			hw_data: otp@128 {
				reg = <128 128>;
			};
			test_data: otp@256 {
				reg = <256 32>;
			};
			mac0: otp@288 {
				reg = <288 6>;
			};
			mac1: otp@294 {
				reg = <294 6>;
			};
			mac2: otp@300 {
				reg = <300 6>;
			};
			mac3: otp@306 {
				reg = <306 6>;
			};
			decode: otp@312 {
				reg = <312 4>;
			};
			user_data1: otp@316 {
				reg = <316 68>;
			};
			priv_k0: otp@384 {
				reg = <384 68>;
			};
		};

		puf@d0003300 {
			compatible = "pufs,puf";
			reg = <0x0 0xd0003300 0x0 0x100>;
			power-domains = <&pd_cpu EA65XX_PD_PUFCC_SAP ALWAYS_ON>;
			#address-cells = <1>;
			#size-cells = <1>;

			uid: uid@0 {
				reg = <0 32>;
			};
		};

		refclk1hz: refclk1hz@0 {
			compatible = "fixed-clock";
			#clock-cells = <0>;
			clock-frequency = <1>;
		};

		rtc0: rtc@d2e00400 {
			compatible = "cdns,rtc-r109v3";
			reg = <0x0 0xd2e00400 0x0 0x0200>;
			status = "okay";
			clock-names = "pclk", "ref_clk";
			clocks = <&sapclk EA65XX_S_APB_CLK>, <&refclk1hz>;
			power-domains = <&pd_rtc EA65XX_PD_RTC_RTC ALWAYS_ON>;
			interrupt-parent = <&plic0>;
			interrupts = <RTC4_IRQn IRQ_TYPE_LEVEL_HIGH>;
		};
		
		cpupwm0: pwm0@c2800000 {
			compatible = "cdns,cdns-pwm";
			reg = <0x0 0xc2800000 0x0 0x1000>;
			status = "okay";
			interrupt-parent = <&plic0>;
			interrupts = <C_PWM0_IRQn IRQ_TYPE_LEVEL_HIGH>;
			power-domains = <&pd_cpu EA65XX_PD_PWM0_CPU ALWAYS_ON>;
			clock-names = "pclk";
			clocks = <&cpuclk EA65XX_PAPB_CLK>;
			#pwm-cells = <3>;
			pinctrl-0 = <&pin_c_pwm0>;
			pinctrl-names = "default";
		};

		sappwm0: pwm0@d2800000 {
			compatible = "cdns,cdns-pwm";
			reg = <0x0 0xd2800000 0x0 0x1000>;
			status = "okay";
			interrupt-parent = <&plic0>;
			interrupts = <S_PWM0_IRQn IRQ_TYPE_LEVEL_HIGH>;
			power-domains = <&pd_sap EA65XX_PD_PWM0_SAP ALWAYS_ON>;
			clock-names = "pclk";
			clocks = <&sapclk EA65XX_S_APB_CLK>;
			pinctrl-0 = <&pin_s_pwm0>;
			pinctrl-names = "default";
			#pwm-cells = <3>;
		};

		rtcpwm0: pwm0@d2e00800 {
			compatible = "cdns,cdns-pwm";
			reg = <0x0 0xd2e00800 0x0 0x1000>;
			status = "okay";
			interrupt-parent = <&plic0>;
			interrupts = <RTC10_IRQn IRQ_TYPE_LEVEL_HIGH>;
			power-domains = <&pd_sap EA65XX_PD_PWM0_RTC ALWAYS_ON>;
			clock-names = "pclk";
			clocks = <&sapclk EA65XX_S_APB_CLK>;
		};

		backlight@0 {
			compatible = "pwm-backlight";
			pwms = <&sappwm0 0 5000000 0>;
			brightness-level = <0 4 8 16 32 64 128 255>;
			default-brightness-level = <7>;
			status = "okay";
		};

		venc@c9000000 {
			compatible = "hx280enc,v1h6";
			reg = <0x0 0xc9000000 0x0 0x4b0>;
			interrupt-parent = <&plic0>;
			interrupts = <C_VENC0_IRQn IRQ_TYPE_LEVEL_HIGH>;
			power-domains = <&pd_cpu EA65XX_PD_VENC0_CPU ALWAYS_ON>;
		};

		venc@c9100000 {
			compatible = "hx280enc,v1h6";
			reg = <0x0 0xc9100000 0x0 0x4b0>;
			interrupt-parent = <&plic0>;
			interrupts = <C_VENC1_IRQn IRQ_TYPE_LEVEL_HIGH>;
			power-domains = <&pd_cpu EA65XX_PD_VENC1_CPU ALWAYS_ON>;
		};

		vdec@c6000000 {
			compatible = "verisilicon,vcd";
			reg = <0x0 0xc6000000 0x0 0x400>,
				<0x0 0xc6000400 0x0 0x400>,
				<0x0 0xc6000800 0x0 0xf00>;
			reg-names = "vcmd", "axife", "vcd";
			interrupts-extended = <&plic0 C_VDEC_IRQn IRQ_TYPE_LEVEL_HIGH>;
			interrupt-names = "vcmd";
			power-domains = <&pd_cpu EA65XX_PD_VDEC_CPU ALWAYS_ON>;
			memory-region = <&vdecmem>;
		};

		mu0: mailbox@c2600000 {
			compatible = "icg,icg-mailbox";
			reg = <0x0 0xc2600000 0x0 0x0080>;
			status = "okay";
			power-domains = <&pd_cpu EA65XX_PD_MU_CPU ALWAYS_ON>;
			interrupt-parent = <&plic0>;
			interrupts = <C_MU_A2B_IRQn IRQ_TYPE_LEVEL_HIGH>,
						 <C_MU_B2A_IRQn IRQ_TYPE_LEVEL_HIGH>;
			interrupt-names = "MU_A2B", "MU_B2A";
			clocks = <&cpuclk EA65XX_MU_CLK>;
			clock-names = "ws_mu_clk";
			#mbox-cells = <1>;
			num_chans = <2>;
		};
		
		mu1: mailbox@d2600000 {
			compatible = "icg,icg-mailbox";
			reg = <0x0 0xd2600000 0x0 0x0080>;
			status = "okay";
			power-domains = <&pd_sap EA65XX_PD_MU_SAP ALWAYS_ON>;
			interrupt-parent = <&plic0>;
			interrupts = <S_MU_A2B_IRQn IRQ_TYPE_LEVEL_HIGH>,
						 <S_MU_B2A_IRQn IRQ_TYPE_LEVEL_HIGH>;
			interrupt-names = "MU_A2B", "MU_B2A";
			clocks = <&sapclk EA65XX_S_MU_CLK>;
			clock-names = "ws_mu_clk";
			#mbox-cells = <1>;
			num_chans = <2>;
		};

		hsm@c2f08c00 {
			compatible = "icg,hsm";
			reg = <0x0 0xc2f08c00 0x0 0x100
                              0x0 0xc2f08e00 0x0 0x100
			>;
		};

		umap@0 {
			compatible = "icg,umap";
			icg,proc_file_cnt = <5>;
			icg,proc_file_names = "logmpp", "mmsys", "npu", "vdec", "venc";
		};

		mailbox_test@0 {
			status 			= "okay";
			compatible      = "mailbox-test";
			mboxes          = <&mu0 0>;
			mbox-names      = "tx";
		};//test purpose only

		env: partition@0 {
			compatible = "u-boot,mmcenv";
			env-config = <0x420000 0x20000>;
			ethaddr: ethaddr {
					#nvmem-cell-cells = <1>;
				nvmem-cell-names = "ethaddr";
			};
		};

		reset@d2e00000 {
			compatible = "icg,icg-reset";
			reg = <0 0xd2e00000 0 0x4>;
		};

		pvt@c2900000 {
			compatible = "baikal,icg-pvt";
			reg = <0 0xc2900000 0 0x1000>;
			power-domains = <&pd_cpu EA65XX_PD_PVT_CPU ALWAYS_ON>;
			#thermal-sensor-cells = <0>;
			interrupt-parent = <&plic0>;
			interrupts = <C_PVT0_IRQn IRQ_TYPE_LEVEL_HIGH>,
						<C_PVT1_IRQn IRQ_TYPE_LEVEL_HIGH>;
			icg,pvt-channel-count = <2>;
			baikal,pvt-temp-offset-millicelsius = <1000>;
			clocks = <&cpuclk EA65XX_PAPB_CLK>;
			clock-names = "pclk";
		};

		dummy_reg_cpu: regulator-virtual {
			compatible = "regulator-virtual";
			regulator-name = "dummy-cpu-supply";
			regulator-min-microvolt = <100000>;
			regulator-max-microvolt = <1500000>;
			regulator-boot-on;
			regulator-always-on;
    	};

		leds {
			compatible = "gpio-leds";

			led1 {
				gpios = <&gpio_cpu 10 GPIO_ACTIVE_LOW>;
			};
		};
		onewire {
			compatible = "w1-gpio";
			gpios = <&gpio_cpu 13 GPIO_ACTIVE_LOW>;
			status = "disabled";
		};
		npu0: npu@c7000000 {
            compatible = "icg,npu";
            reg = <0x0 0xc7000000 0x0 0x1000000>;
			reg-names = "core_major";
            clocks = <&cpuclk EA65XX_VIP0_CLK>;
			clock-names = "core_major";
			power-domains = <&pd_cpu EA65XX_PD_NPU_CPU ALWAYS_ON>;
			power-domain-names = "core_major";
			interrupt-parent = <&plic0>;
            interrupts = <C_NPU0_IRQn IRQ_TYPE_LEVEL_HIGH>;
			interrupt-names = "core_major";
			contiguous-base = <0x1 0x70000000>;
			contiguous-size = <0x8000000>;
			status = "okay"; 
        };
	}; // soc end
	system {
		compatible = "icg,ea65xx";
		linux,revision = <0x889980>;
		// rasp pi style revision code
		// 1000 1000 1001 1001 1000 0000
		// Mark Manu Proc Type      rev 
	};
};

&mmc0 {
	status = "okay";
};

&mmc1 {
	status = "okay";
};

&cpu0 {
	clocks = <&cpuclk EA65XX_CPU_CLK>;
	operating-points-v2 = <&cpu0_opp_table>;
	cpu-supply = <&dummy_reg_cpu>;
};

&cpu1 {
	clocks = <&cpuclk EA65XX_CPU_CLK>;
	operating-points-v2 = <&cpu0_opp_table>;
	cpu-supply = <&dummy_reg_cpu>;
};

&cpu4 {
	clocks = <&cpuclk EA65XX_CPU_CLK>;
	operating-points-v2 = <&cpu0_opp_table>;
	cpu-supply = <&dummy_reg_cpu>;
};


